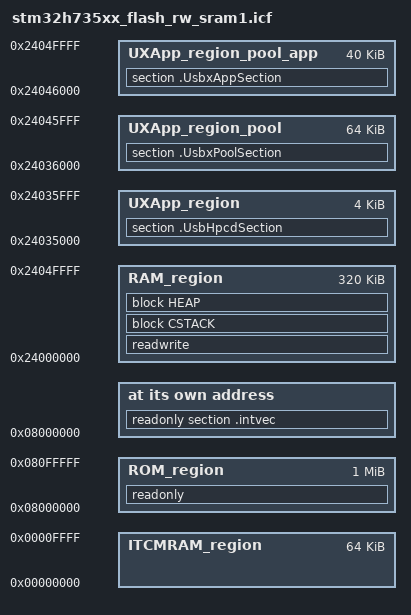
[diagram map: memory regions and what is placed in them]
/*###ICF### Section handled by ICF editor, don't touch! ****/
/*-Editor annotation file-*/
/* IcfEditorFile="$TOOLKIT_DIR$\config\ide\IcfEditor\cortex_v1_0.xml" */
/*-Specials-*/
define symbol __ICFEDIT_intvec_start__ = 0x08000000;
/*-Memory Regions-*/
define symbol __ICFEDIT_region_ROM_start__     = 0x08000000;
define symbol __ICFEDIT_region_ROM_end__       = 0x080FFFFF;
define symbol __ICFEDIT_region_RAM_start__     = 0x24000000;
define symbol __ICFEDIT_region_RAM_end__       = 0x2404FFFF;
define symbol __ICFEDIT_region_ITCMRAM_start__ = 0x00000000;
define symbol __ICFEDIT_region_ITCMRAM_end__   = 0x0000FFFF;
define symbol __ICFEDIT_region_UXDATA_start__  = 0x24035000;
define symbol __ICFEDIT_region_UXDATA_end__   = 0x24035FFF;
define symbol __ICFEDIT_region_UXDATA_POOL_start__  = 0x24036000;
define symbol __ICFEDIT_region_UXDATA_POOL_end__   = 0x24045FFF;
define symbol __ICFEDIT_region_UXDATA_POOL_APP_start__  = 0x24046000;
define symbol __ICFEDIT_region_UXDATA_POOL_APP_end__   = __ICFEDIT_region_RAM_end__;

/*-Sizes-*/
define symbol __ICFEDIT_size_cstack__ = 0x400;
define symbol __ICFEDIT_size_heap__   = 0x200;
/**** End of ICF editor section. ###ICF###*/


define memory mem with size = 4G;
define region ROM_region      = mem:[from __ICFEDIT_region_ROM_start__   to __ICFEDIT_region_ROM_end__];
define region RAM_region      = mem:[from __ICFEDIT_region_RAM_start__   to __ICFEDIT_region_RAM_end__];
define region ITCMRAM_region  = mem:[from __ICFEDIT_region_ITCMRAM_start__ to __ICFEDIT_region_ITCMRAM_end__];
define region UXApp_region = mem:[from __ICFEDIT_region_UXDATA_start__ to __ICFEDIT_region_UXDATA_end__];
define region UXApp_region_pool = mem:[from __ICFEDIT_region_UXDATA_POOL_start__ to __ICFEDIT_region_UXDATA_POOL_end__];
define region UXApp_region_pool_app = mem:[from __ICFEDIT_region_UXDATA_POOL_APP_start__ to __ICFEDIT_region_UXDATA_POOL_APP_end__];

define block CSTACK    with alignment = 8, size = __ICFEDIT_size_cstack__   { };
define block HEAP      with alignment = 8, size = __ICFEDIT_size_heap__     { };

initialize by copy { readwrite };
do not initialize  { section .noinit };

place at address mem:__ICFEDIT_intvec_start__ { readonly section .intvec };

place in ROM_region   { readonly };
place in RAM_region   { readwrite,
                        block CSTACK, block HEAP };
place in UXApp_region { section .UsbHpcdSection};
place in UXApp_region_pool { section .UsbxPoolSection};
place in UXApp_region_pool_app { section .UsbxAppSection};
